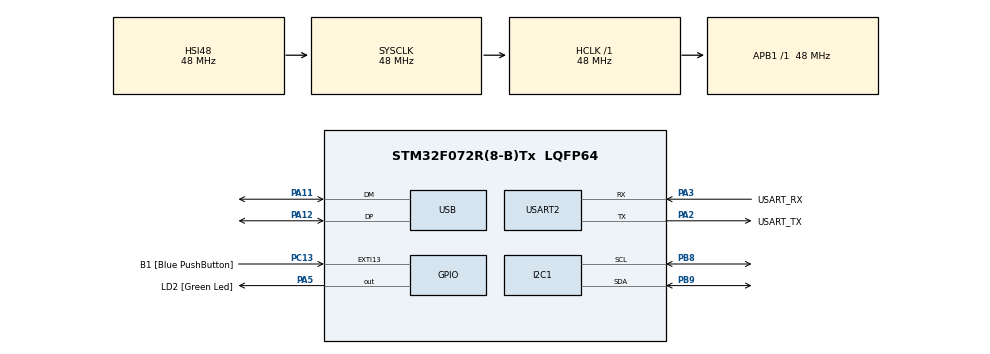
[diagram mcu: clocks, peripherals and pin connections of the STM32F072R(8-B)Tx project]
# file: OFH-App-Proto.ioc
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FREERTOS.Tasks01=fanDriverTask,24,128,StartFanDriverTask,Default,NULL,Static,fanDriverTaskBuffer,fanDriverTaskControlBlock;tUsbTask,40,512,StartTUsbTask,Default,NULL,Static,tUsbTaskBuffer,tUsbTaskControlBlock;cdcTask,24,128,StartCdcTask,Default,NULL,Static,cdcTaskBuffer,cdcTaskControlBlock;ledTask,8,128,StartLedTask,Default,NULL,Static,ledTaskBuffer,ledTaskControlBlock
I2C1.Timing=0x00201D2B
Mcu.Family=STM32F0
Mcu.Name=STM32F072R(8-B)Tx
Mcu.Package=LQFP64
NVIC.TIM1_BRK_UP_TRG_COM_IRQn=true\:3\:0\:false\:false\:true\:false\:false\:true\:true
NVIC.TimeBase=TIM1_BRK_UP_TRG_COM_IRQn
NVIC.TimeBaseIP=TIM1
NVIC.USB_IRQn=true\:3\:0\:false\:false\:true\:true\:true\:true\:true
PA11.Mode=Device
PA11.Signal=USB_DM
PA12.Mode=Device
PA12.Signal=USB_DP
PA13.GPIO_Label=TMS
PA13.Mode=Serial_Wire
PA13.Signal=SYS_SWDIO
PA14.GPIO_Label=TCK
PA14.Mode=Serial_Wire
PA14.Signal=SYS_SWCLK
PA2.GPIO_Label=USART_TX
PA2.GPIO_Mode=GPIO_MODE_AF_PP
PA2.GPIO_PuPd=GPIO_NOPULL
PA2.GPIO_Speed=GPIO_SPEED_FREQ_LOW
PA2.Mode=Asynchronous
PA2.Signal=USART2_TX
PA3.GPIO_Label=USART_RX
PA3.GPIO_Mode=GPIO_MODE_AF_PP
PA3.GPIO_PuPd=GPIO_NOPULL
PA3.GPIO_Speed=GPIO_SPEED_FREQ_LOW
PA3.Mode=Asynchronous
PA3.Signal=USART2_RX
PA5.GPIO_Label=LD2 [Green Led]
PA5.GPIO_Mode=GPIO_MODE_OUTPUT_PP
PA5.GPIO_PuPd=GPIO_NOPULL
PA5.GPIO_Speed=GPIO_SPEED_FREQ_LOW
PA5.Signal=GPIO_Output
PB8.Mode=I2C
PB8.Signal=I2C1_SCL
PB9.Mode=I2C
PB9.Signal=I2C1_SDA
PC13.GPIO_Label=B1 [Blue PushButton]
PC13.GPIO_ModeDefaultEXTI=GPIO_MODE_IT_FALLING
PC13.Signal=GPXTI13
PC14-OSC32_IN.Mode=LSE-External-Oscillator
PC14-OSC32_IN.Signal=RCC_OSC32_IN
PC15-OSC32_OUT.Mode=LSE-External-Oscillator
PC15-OSC32_OUT.Signal=RCC_OSC32_OUT
PF0-OSC_IN.Mode=HSE-External-Clock-Source
PF0-OSC_IN.Signal=RCC_OSC_IN
PF1-OSC_OUT.Signal=RCC_OSC_OUT
ProjectManager.HeapSize=0x200
ProjectManager.StackSize=0x400
ProjectManager.TargetToolchain=Makefile
RCC.AHBFreq_Value=48000000
RCC.APB1Freq_Value=48000000
RCC.APB1TimFreq_Value=48000000
RCC.FLatency-AdvancedSettings=FLASH_LATENCY_1
RCC.HCLKFreq_Value=48000000
RCC.PLLDivider=RCC_PREDIV_DIV2
RCC.PLLMUL=RCC_PLL_MUL12
RCC.PREFETCH_ENABLE-AdvancedSettings=1
RCC.SYSCLKFreq_VALUE=48000000
RCC.SYSCLKSource=RCC_SYSCLKSOURCE_HSI48
USART2.VirtualMode=VM_ASYNC
USART2.VirtualMode-Asynchronous=VM_ASYNC
VP_CRC_VS_CRC.Mode=CRC_Activate
VP_FREERTOS_VS_CMSIS_V2.Mode=CMSIS_V2
VP_SYS_VS_tim1.Mode=TIM1
board=NUCLEO-F072RB

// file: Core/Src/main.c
/* USER CODE BEGIN Header */
/**
  ******************************************************************************
  * @file           : main.c
  * @brief          : Main program body
  ******************************************************************************
  * @attention
  *
  * Copyright (c) 2024 STMicroelectronics.
  * All rights reserved.
  *
  * This software is licensed under terms that can be found in the LICENSE file
  * in the root directory of this software component.
  * If no LICENSE file comes with this software, it is provided AS-IS.
  *
  ******************************************************************************
  */
/* USER CODE END Header */
#include "main.h"
#include "cmsis_os.h"
#include "crc.h"
#include "i2c.h"
#include "usart.h"
#include "usb.h"
#include "gpio.h"

/* USER CODE BEGIN Includes */
#include "app.h"

/* USER CODE END Includes */

void SystemClock_Config(void);
void MX_FREERTOS_Init(void);

int main(void)
{

  /* MCU Configuration--------------------------------------------------------*/

  /* Reset of all peripherals, Initializes the Flash interface and the Systick. */
  HAL_Init();

  /* Configure the system clock */
  SystemClock_Config();

  /* Initialize all configured peripherals */
  MX_GPIO_Init();
  MX_USART2_UART_Init();
  MX_I2C1_Init();
  MX_USB_PCD_Init();
  MX_CRC_Init();
  /* USER CODE BEGIN 2 */
  initOpenFanHub();

  /* USER CODE END 2 */

  /* Init scheduler */
  osKernelInitialize();

  /* Call init function for freertos objects (in cmsis_os2.c) */
  MX_FREERTOS_Init();

  /* Start scheduler */
  osKernelStart();

  /* We should never get here as control is now taken by the scheduler */

  /* Infinite loop */
  while (1)
  {

  }
}

void SystemClock_Config(void)
{
  RCC_OscInitTypeDef RCC_OscInitStruct = {0};
  RCC_ClkInitTypeDef RCC_ClkInitStruct = {0};
  RCC_PeriphCLKInitTypeDef PeriphClkInit = {0};

  /** Initializes the RCC Oscillators according to the specified parameters
  * in the RCC_OscInitTypeDef structure.
  */
  RCC_OscInitStruct.OscillatorType = RCC_OSCILLATORTYPE_HSI|RCC_OSCILLATORTYPE_HSI48;
  RCC_OscInitStruct.HSIState = RCC_HSI_ON;
  RCC_OscInitStruct.HSI48State = RCC_HSI48_ON;
  RCC_OscInitStruct.HSICalibrationValue = RCC_HSICALIBRATION_DEFAULT;
  RCC_OscInitStruct.PLL.PLLState = RCC_PLL_NONE;
  if (HAL_RCC_OscConfig(&RCC_OscInitStruct) != HAL_OK)
  {
    Error_Handler();
  }

  /** Initializes the CPU, AHB and APB buses clocks
  */
  RCC_ClkInitStruct.ClockType = RCC_CLOCKTYPE_HCLK|RCC_CLOCKTYPE_SYSCLK
                              |RCC_CLOCKTYPE_PCLK1;
  RCC_ClkInitStruct.SYSCLKSource = RCC_SYSCLKSOURCE_HSI48;
  RCC_ClkInitStruct.AHBCLKDivider = RCC_SYSCLK_DIV1;
  RCC_ClkInitStruct.APB1CLKDivider = RCC_HCLK_DIV1;

  if (HAL_RCC_ClockConfig(&RCC_ClkInitStruct, FLASH_LATENCY_1) != HAL_OK)
  {
    Error_Handler();
  }
  PeriphClkInit.PeriphClockSelection = RCC_PERIPHCLK_USB|RCC_PERIPHCLK_USART2
                              |RCC_PERIPHCLK_I2C1;
  PeriphClkInit.Usart2ClockSelection = RCC_USART2CLKSOURCE_PCLK1;
  PeriphClkInit.I2c1ClockSelection = RCC_I2C1CLKSOURCE_HSI;
  PeriphClkInit.UsbClockSelection = RCC_USBCLKSOURCE_HSI48;

  if (HAL_RCCEx_PeriphCLKConfig(&PeriphClkInit) != HAL_OK)
  {
    Error_Handler();
  }
}

void HAL_TIM_PeriodElapsedCallback(TIM_HandleTypeDef *htim)
{
  if (htim->Instance == TIM1) {
    HAL_IncTick();
  }
}

void Error_Handler(void)
{
  __disable_irq();
  while (1)
  {
  }
}

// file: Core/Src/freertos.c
/* USER CODE BEGIN Header */
/**
  ******************************************************************************
  * File Name          : freertos.c
  * Description        : Code for freertos applications
  ******************************************************************************
  * @attention
  *
  * Copyright (c) 2024 STMicroelectronics.
  * All rights reserved.
  *
  * This software is licensed under terms that can be found in the LICENSE file
  * in the root directory of this software component.
  * If no LICENSE file comes with this software, it is provided AS-IS.
  *
  ******************************************************************************
  */
/* USER CODE END Header */

#include "FreeRTOS.h"
#include "task.h"
#include "main.h"
#include "cmsis_os.h"

/* USER CODE BEGIN Includes */
#include "app.h"
#include "tusb.h"

/* USER CODE END Includes */

typedef StaticTask_t osStaticThreadDef_t;

/* Definitions for fanDriverTask */
osThreadId_t fanDriverTaskHandle;
uint32_t fanDriverTaskBuffer[ 128 ];
osStaticThreadDef_t fanDriverTaskControlBlock;
const osThreadAttr_t fanDriverTask_attributes = {
  .name = "fanDriverTask",
  .cb_mem = &fanDriverTaskControlBlock,
  .cb_size = sizeof(fanDriverTaskControlBlock),
  .stack_mem = &fanDriverTaskBuffer[0],
  .stack_size = sizeof(fanDriverTaskBuffer),
  .priority = (osPriority_t) osPriorityNormal,
};
/* Definitions for tUsbTask */
osThreadId_t tUsbTaskHandle;
uint32_t tUsbTaskBuffer[ 512 ];
osStaticThreadDef_t tUsbTaskControlBlock;
const osThreadAttr_t tUsbTask_attributes = {
  .name = "tUsbTask",
  .cb_mem = &tUsbTaskControlBlock,
  .cb_size = sizeof(tUsbTaskControlBlock),
  .stack_mem = &tUsbTaskBuffer[0],
  .stack_size = sizeof(tUsbTaskBuffer),
  .priority = (osPriority_t) osPriorityHigh,
};
/* Definitions for cdcTask */
osThreadId_t cdcTaskHandle;
uint32_t cdcTaskBuffer[ 128 ];
osStaticThreadDef_t cdcTaskControlBlock;
const osThreadAttr_t cdcTask_attributes = {
  .name = "cdcTask",
  .cb_mem = &cdcTaskControlBlock,
  .cb_size = sizeof(cdcTaskControlBlock),
  .stack_mem = &cdcTaskBuffer[0],
  .stack_size = sizeof(cdcTaskBuffer),
  .priority = (osPriority_t) osPriorityNormal,
};
/* Definitions for ledTask */
osThreadId_t ledTaskHandle;
uint32_t ledTaskBuffer[ 128 ];
osStaticThreadDef_t ledTaskControlBlock;
const osThreadAttr_t ledTask_attributes = {
  .name = "ledTask",
  .cb_mem = &ledTaskControlBlock,
  .cb_size = sizeof(ledTaskControlBlock),
  .stack_mem = &ledTaskBuffer[0],
  .stack_size = sizeof(ledTaskBuffer),
  .priority = (osPriority_t) osPriorityLow,
};

void StartFanDriverTask(void *argument);
void StartTUsbTask(void *argument);
void StartCdcTask(void *argument);
void StartLedTask(void *argument);

void MX_FREERTOS_Init(void); /* (MISRA C 2004 rule 8.1) */

void MX_FREERTOS_Init(void) {

  /* Create the thread(s) */
  /* creation of fanDriverTask */
  fanDriverTaskHandle = osThreadNew(StartFanDriverTask, NULL, &fanDriverTask_attributes);

  /* creation of tUsbTask */
  tUsbTaskHandle = osThreadNew(StartTUsbTask, NULL, &tUsbTask_attributes);

  /* creation of cdcTask */
  cdcTaskHandle = osThreadNew(StartCdcTask, NULL, &cdcTask_attributes);

  /* creation of ledTask */
  ledTaskHandle = osThreadNew(StartLedTask, NULL, &ledTask_attributes);

}

void StartFanDriverTask(void *argument)
{
  /* USER CODE BEGIN StartFanDriverTask */
  (void) argument;
  /* Infinite loop */
  for(;;)
  {
    fanDriverLoop();
  }
  /* USER CODE END StartFanDriverTask */
}

void StartTUsbTask(void *argument)
{
  /* USER CODE BEGIN StartTUsbTask */
  (void) argument;
  tud_init(BOARD_TUD_RHPORT);
  /* Infinite loop */
  for(;;)
  {
    tUsbLoop();
  }
  /* USER CODE END StartTUsbTask */
}

void StartCdcTask(void *argument)
{
  /* USER CODE BEGIN StartCdcTask */
  (void) argument;
  /* Infinite loop */
  for(;;)
  {
    cdcLoop();
  }
  /* USER CODE END StartCdcTask */
}

void StartLedTask(void *argument)
{
  /* USER CODE BEGIN StartLedTask */
  (void) argument;
  /* Infinite loop */
  for(;;)
  {
    ledLoop();
  }
  /* USER CODE END StartLedTask */
}
